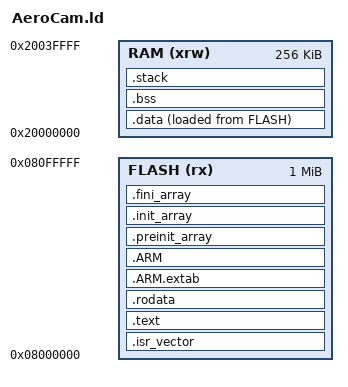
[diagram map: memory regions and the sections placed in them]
/*
 * MIT License
 *
 * Copyright (c) 2026 AeroCam contributors
 *
 * Permission is hereby granted, free of charge, to any person obtaining a copy
 * of this software and associated documentation files (the "Software"), to deal
 * in the Software without restriction, including without limitation the rights
 * to use, copy, modify, merge, publish, distribute, sublicense, and/or sell
 * copies of the Software, and to permit persons to whom the Software is
 * furnished to do so, subject to the following conditions:
 *
 * The above copyright notice and this permission notice shall be included in all
 * copies or substantial portions of the Software.
 *
 * THE SOFTWARE IS PROVIDED "AS IS", WITHOUT WARRANTY OF ANY KIND, EXPRESS OR
 * IMPLIED, INCLUDING BUT NOT LIMITED TO THE WARRANTIES OF MERCHANTABILITY,
 * FITNESS FOR A PARTICULAR PURPOSE AND NONINFRINGEMENT. IN NO EVENT SHALL THE
 * AUTHORS OR COPYRIGHT HOLDERS BE LIABLE FOR ANY CLAIM, DAMAGES OR OTHER
 * LIABILITY, WHETHER IN AN ACTION OF CONTRACT, TORT OR OTHERWISE, ARISING FROM,
 * OUT OF OR IN CONNECTION WITH THE SOFTWARE OR THE USE OR OTHER DEALINGS IN THE
 * SOFTWARE.
 */

/* Generic STM32-style linker script for AeroCam. */

ENTRY(Reset_Handler)

/* Reserve stack space only. No heap/dynamic allocation region is defined. */
_Min_Stack_Size = 0x400;

MEMORY
{
  FLASH (rx)  : ORIGIN = 0x08000000, LENGTH = 1024K
  RAM   (xrw) : ORIGIN = 0x20000000, LENGTH = 256K
}

/* Initial stack pointer, consumed by the vector table. */
_estack = ORIGIN(RAM) + LENGTH(RAM);

SECTIONS
{
  .isr_vector :
  {
    . = ALIGN(4);
    KEEP(*(.isr_vector))
    KEEP(*(.isr_vector.*))
    . = ALIGN(4);
  } > FLASH

  .text :
  {
    . = ALIGN(4);
    *(.text)
    *(.text*)
    *(.glue_7)
    *(.glue_7t)
    *(.eh_frame)

    KEEP(*(.init))
    KEEP(*(.fini))

    . = ALIGN(4);
  } > FLASH

  .rodata :
  {
    . = ALIGN(4);
    *(.rodata)
    *(.rodata*)
    . = ALIGN(4);
  } > FLASH

  .ARM.extab :
  {
    . = ALIGN(4);
    *(.ARM.extab* .gnu.linkonce.armextab.*)
    . = ALIGN(4);
  } > FLASH

  .ARM :
  {
    . = ALIGN(4);
    __exidx_start = .;
    *(.ARM.exidx*)
    __exidx_end = .;
    . = ALIGN(4);
  } > FLASH

  .preinit_array :
  {
    . = ALIGN(4);
    PROVIDE_HIDDEN(__preinit_array_start = .);
    KEEP(*(.preinit_array*))
    PROVIDE_HIDDEN(__preinit_array_end = .);
    . = ALIGN(4);
  } > FLASH

  .init_array :
  {
    . = ALIGN(4);
    PROVIDE_HIDDEN(__init_array_start = .);
    KEEP(*(SORT(.init_array.*)))
    KEEP(*(.init_array*))
    PROVIDE_HIDDEN(__init_array_end = .);
    . = ALIGN(4);
  } > FLASH

  .fini_array :
  {
    . = ALIGN(4);
    PROVIDE_HIDDEN(__fini_array_start = .);
    KEEP(*(SORT(.fini_array.*)))
    KEEP(*(.fini_array*))
    PROVIDE_HIDDEN(__fini_array_end = .);
    . = ALIGN(4);
  } > FLASH

  _etext = .;

  .data :
  {
    . = ALIGN(4);
    _sdata = .;
    *(.data)
    *(.data*)
    . = ALIGN(4);
    _edata = .;
  } > RAM AT > FLASH

  .bss (NOLOAD) :
  {
    . = ALIGN(4);
    _sbss = .;
    *(.bss)
    *(.bss*)
    *(COMMON)
    . = ALIGN(4);
    _ebss = .;
    end = .;
    __end = .;
    _end = .;
    __end__ = .;
  } > RAM

  .stack ORIGIN(RAM) + LENGTH(RAM) - _Min_Stack_Size (NOLOAD) :
  {
    . = ALIGN(8);
    __StackLimit = .;
    . = . + _Min_Stack_Size;
    . = ALIGN(8);
    __StackTop = .;
  } > RAM

  /DISCARD/ :
  {
    *(.note.GNU-stack)
    *(.comment)
  }
}

ASSERT(__StackTop == _estack, "Stack top must match the end of RAM")
